# ADuCM320i register map
Vendor: Analog Devices Inc.; Series: ARMCM3; File version: 1.0
CPU: CM3 r2p1, little endian, no MPU, no FPU, 3 interrupt priority bits
Registers are 16-bit, read-write, no defined reset value unless marked. A register's access mark holds for its fields unless they carry their own. Offsets are from the block's base; [hi:lo] are bit positions.

## LV_INT — Low voltage die interrupt configuration
Base 0x40083004
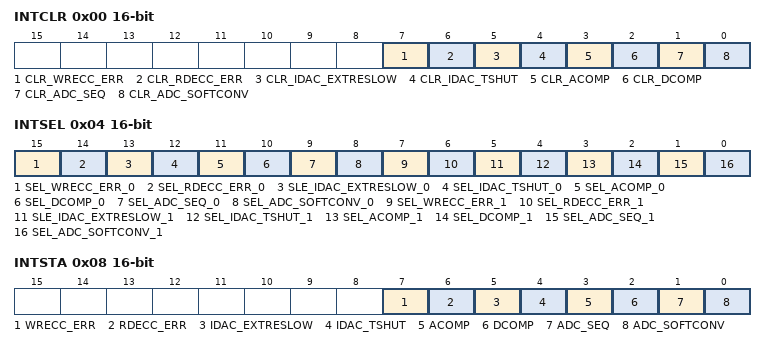
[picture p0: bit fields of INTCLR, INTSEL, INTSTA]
0x00 INTCLR wo — Interrupt clear register
  [7] CLR_WRECC_ERR range 0x00000000..0x00000001 — Write 1 to this bit to clear the write ECC error interrupt flag
  [6] CLR_RDECC_ERR range 0x00000000..0x00000001 — Write 1 to this bit to clear the read ECC error interrupt flag
  [5] CLR_IDAC_EXTRESLOW range 0x00000000..0x00000001 — Write 1 to this bit to clear the IDAC EXTRESLOW interrupt flag
  [4] CLR_IDAC_TSHUT range 0x00000000..0x00000001 — Write 1 to this bit to clear the IDAC TSHUT interrupt flag
  [3] CLR_ACOMP range 0x00000000..0x00000001 — Write 1 to this bit to clear the analog compare interrupt flag
  [2] CLR_DCOMP range 0x00000000..0x00000001 — Write 1 to this bit to clear the digital compare interrupt flag
  [1] CLR_ADC_SEQ range 0x00000000..0x00000001 — Write 1 to this bit to clear the ADC sequence conversion interrupt flag
  [0] CLR_ADC_SOFTCONV range 0x00000000..0x00000001 — Write 1 to this bit to clear the ADC software conversion interrupt flag
0x04 INTSEL — Interrupt mask register
  [15] SEL_WRECC_ERR_0 range 0x00000000..0x00000001 — Write 1 to this bit to enable write ECC error interrupt for interrupt pin 0
  [14] SEL_RDECC_ERR_0 range 0x00000000..0x00000001 — Write 1 to this bit to enable read ECC error interrupt for interrupt pin 0
  [13] SLE_IDAC_EXTRESLOW_0 range 0x00000000..0x00000001 — Write 1 to this bit to enable IDAC EXTRESLOW interrupt for interrupt pin 0
  [12] SEL_IDAC_TSHUT_0 range 0x00000000..0x00000001 — Write 1 to this bit to enable IDAC TSHUT interrupt for interrupt pin 0
  [11] SEL_ACOMP_0 range 0x00000000..0x00000001 — Write 1 to this bit to enable analog comparator interrupt for interrupt pin 0
  [10] SEL_DCOMP_0 range 0x00000000..0x00000001 — Write 1 to this bit to enable digital comparator interrupt for interrupt pin 0
  [9] SEL_ADC_SEQ_0 range 0x00000000..0x00000001 — Write 1 to this bit to enable ADC sequence conversion interrupt for interrupt pin 0
  [8] SEL_ADC_SOFTCONV_0 range 0x00000000..0x00000001 — Write 1 to this bit to enable ADC software conversion interrupt for interrupt pin 0
  [7] SEL_WRECC_ERR_1 range 0x00000000..0x00000001 — Write 1 to this bit to enable write ECC error interrupt for interrupt pin 1
  [6] SEL_RDECC_ERR_1 range 0x00000000..0x00000001 — Write 1 to this bit to enable read ECC error interrupt for interrupt pin 1
  [5] SLE_IDAC_EXTRESLOW_1 range 0x00000000..0x00000001 — Write 1 to this bit to enable IDAC EXTRESLOW interrupt for interrupt pin 1
  [4] SEL_IDAC_TSHUT_1 range 0x00000000..0x00000001 — Write 1 to this bit to enable IDAC TSHUT interrupt for interrupt pin 1
  [3] SEL_ACOMP_1 range 0x00000000..0x00000001 — Write 1 to this bit to enable analog comparator interrupt for interrupt pin 1
  [2] SEL_DCOMP_1 range 0x00000000..0x00000001 — Write 1 to this bit to enable digital comparator interrupt for interrupt pin 1
  [1] SEL_ADC_SEQ_1 range 0x00000000..0x00000001 — Write 1 to this bit to enable ADC sequence conversion interrupt for interrupt pin 1
  [0] SEL_ADC_SOFTCONV_1 range 0x00000000..0x00000001 — Write 1 to this bit to enable ADC software conversion interrupt for interrupt pin 1
0x08 INTSTA ro — Interrupt status register
  [7] WRECC_ERR range 0x00000000..0x00000001 — Write data ECC error interrupt status
  [6] RDECC_ERR range 0x00000000..0x00000001 — Read data ECC error interrupt status
  [5] IDAC_EXTRESLOW range 0x00000000..0x00000001 — IDAC EXTRESLOW interrupt status
  [4] IDAC_TSHUT range 0x00000000..0x00000001 — IDAC temperature TSHT interrupt status
  [3] ACOMP range 0x00000000..0x00000001 — Analog comparator interrupt status
  [2] DCOMP range 0x00000000..0x00000001 — Digital comparator interrupt status
  [1] ADC_SEQ range 0x00000000..0x00000001 — ADC sequence interrupt status
  [0] ADC_SOFTCONV range 0x00000000..0x00000001 — ADC software conversion interrupt status
